# MMCSD2_ECC_AGGR_TXMEM register map
Vendor: Texas Instruments
Peripheral module from a debugger description file (folder J7ES).
Registers are 32-bit, access not given, reset 0x0 unless marked. A register's access mark holds for its fields unless they carry their own. Offsets are as the file gives them; lines under a group give offsets from that group; [hi:lo] are bit positions; {n}, {i} and the like mark numbered series; 'fields as' and 'values as' point back to an identical list; <NAME> marks a mode.

## MMCSD2_ECC_AGGR_TXMEM
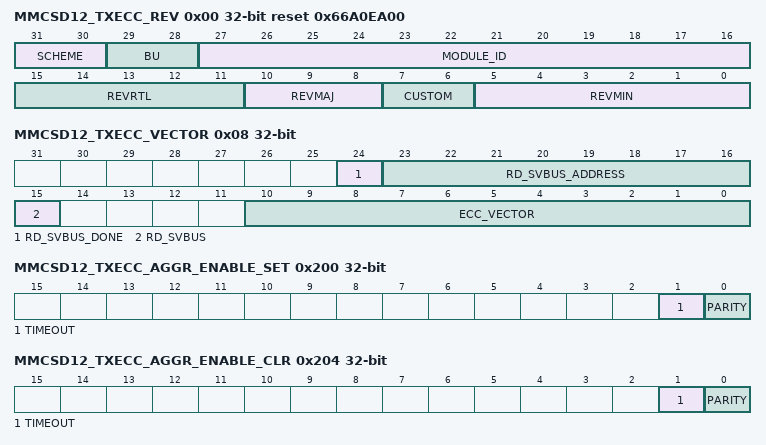
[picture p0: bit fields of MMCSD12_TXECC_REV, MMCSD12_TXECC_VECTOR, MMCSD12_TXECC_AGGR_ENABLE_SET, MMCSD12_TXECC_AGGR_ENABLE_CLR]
0x00 MMCSD12_TXECC_REV ro reset 0x66A0EA00 — Aggregator Revision Register Revision parameters.
  [31:30] SCHEME
  [29:28] BU — Business Unit
  [27:16] MODULE_ID
  [15:11] REVRTL — RTL Version
  [10:8] REVMAJ — Major Version
  [7:6] CUSTOM — Custom Version
  [5:0] REVMIN — Minor Version
0x08 MMCSD12_TXECC_VECTOR — ECC Vector Register
  [24] RD_SVBUS_DONE — Read Done Status to indicate if read on the serial ECC interface is complete, write of any value will clear this bit. (access RW1C)
  [23:16] RD_SVBUS_ADDRESS rw — Read Address
  [15] RD_SVBUS — Read Trigger Write 1h to trigger a read on the serial ECC interface. (access RW1S)
  [10:0] ECC_VECTOR rw — ECC RAM ID Value written to select the corresponding ECC RAM for control or status.
0x0C MMCSD12_TXECC_STAT ro reset 0x1 — Misc Status Register
  [10:0] NUM_RAMS — Indicates the number of RAMs serviced by the ECC aggregator.
0x3C MMCSD12_TXECC_SEC_EOI_REG — SEC EOI Register The EOI register is used to re-trigger the pulse interrupt signal to ensure that any nested interrupt events are serviced. The software interrupt handler must write to the EOI register at the end of the current interrupt processing routine, so that new events can re-trigger the pulse interrupt signal again. For level interrupt signals the EOI register is not functional and must not be used.
  [0] EOI_WR — SEC EOI (access RW1S)
0x40 MMCSD12_TXECC_SEC_STATUS_REG0 — SEC Interrupt Status Register 0
  [0] TXMEM_PEND — Interrupt Pending Status for txmem_pend (access RW1S)
0x80 MMCSD12_TXECC_SEC_ENABLE_SET_REG0 — SEC Interrupt Enable Set Register 0
  [0] TXMEM_ENABLE_SET — Interrupt Enable Set for txmem_pend (access RW1S)
0xC0 MMCSD12_TXECC_SEC_ENABLE_CLR_REG0 — SEC Interrupt Enable Clear Register 0
  [0] TXMEM_ENABLE_CLR — Interrupt Enable Clear for txmem_pend (access RW1C)
0x13C MMCSD12_TXECC_DED_EOI_REG — DED EOI Register The EOI register is used to re-trigger the pulse interrupt signal to ensure that any nested interrupt events are serviced. The software interrupt handler must write to the EOI register at the end of the current interrupt processing routine, so that new events can re-trigger the pulse interrupt signal again. For level interrupt signals the EOI register is not functional and must not be used.
  [0] EOI_WR — DED EOI (access RW1S)
0x140 MMCSD12_TXECC_DED_STATUS_REG0 — DED Interrupt Status Register 0
  fields as MMCSD12_TXECC_SEC_STATUS_REG0
0x180 MMCSD12_TXECC_DED_ENABLE_SET_REG0 — DED Interrupt Enable Set Register 0
  fields as MMCSD12_TXECC_SEC_ENABLE_SET_REG0
0x1C0 MMCSD12_TXECC_DED_ENABLE_CLR_REG0 — DED Interrupt Enable Clear Register 0
  fields as MMCSD12_TXECC_SEC_ENABLE_CLR_REG0
0x200 MMCSD12_TXECC_AGGR_ENABLE_SET — Aggregator Interrupt Enable Set Register
  [1] TIMEOUT — Interrupt enable set for serial ECC interface timeout errors (access RW1S)
  [0] PARITY — Interrupt enable set for parity errors (access RW1S)
0x204 MMCSD12_TXECC_AGGR_ENABLE_CLR — Aggregator Interrupt Enable Clear Register
  [1] TIMEOUT — Interrupt enable clear for serial ECC interface timeout errors (access RW1C)
  [0] PARITY — Interrupt enable clear for parity errors (access RW1C)
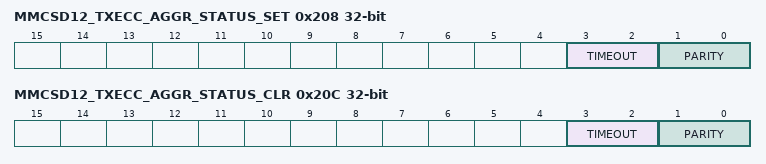
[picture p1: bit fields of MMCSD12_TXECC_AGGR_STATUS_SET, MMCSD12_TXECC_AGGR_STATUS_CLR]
0x208 MMCSD12_TXECC_AGGR_STATUS_SET — Aggregator Interrupt Status Set Register
  [3:2] TIMEOUT — Interrupt status set for serial ECC interface timeout errors (access RWincr)
  [1:0] PARITY — Interrupt status set for parity errors (access RWincr)
0x20C MMCSD12_TXECC_AGGR_STATUS_CLR — Aggregator Interrupt Status Clear Register
  [3:2] TIMEOUT — Interrupt status clear for serial ECC interface timeout errors (access RWdecr)
  [1:0] PARITY — Interrupt status clear for parity errors (access RWdecr)
